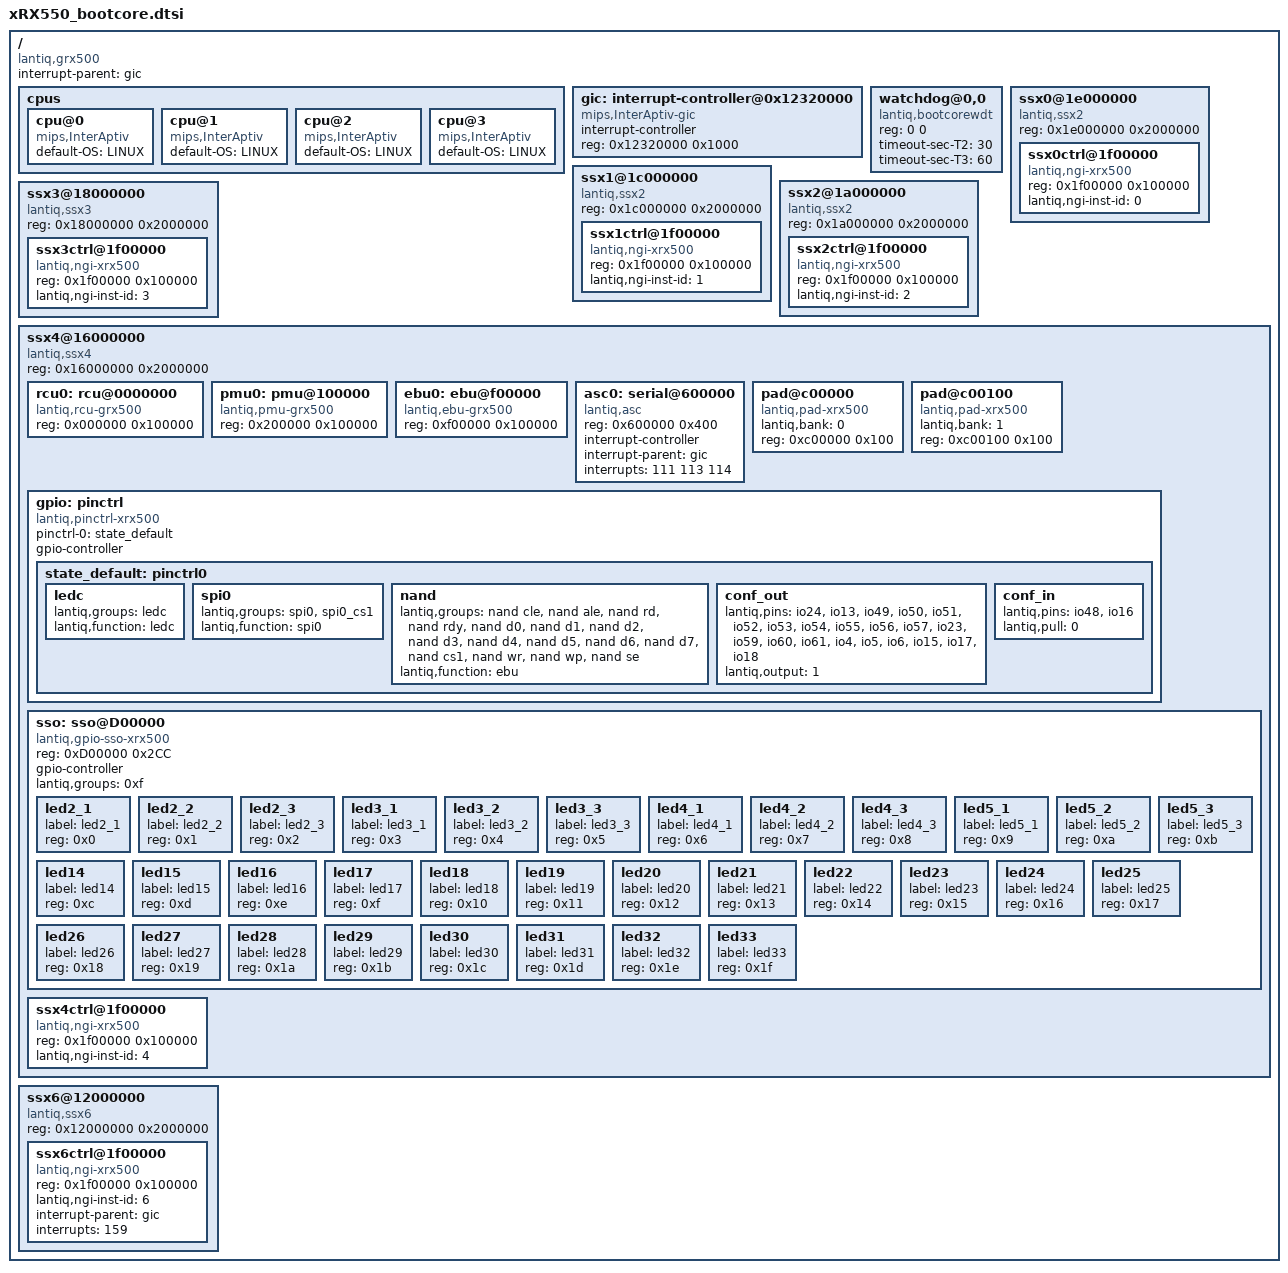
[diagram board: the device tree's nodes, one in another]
/ {
	#address-cells = <1>;
	#size-cells = <1>;
	compatible = "lantiq,grx500","lantiq,xway";
        interrupt-parent = <&gic>;

	cpus {
		cpu@0 {
			compatible = "mips,InterAptiv";
			default-OS = "LINUX";
		};
		cpu@1 {
			compatible = "mips,InterAptiv";
			default-OS = "LINUX";
		};
		cpu@2 {
			compatible = "mips,InterAptiv";
			default-OS = "LINUX";
		};
		cpu@3 {
			compatible = "mips,InterAptiv";
			default-OS = "LINUX";
		};
	};

        gic: interrupt-controller@0x12320000 {
                compatible = "mips,InterAptiv-gic";
                #interrupt-cells = <1>;
                #address-cells = <0>;
                interrupt-controller;
                reg = <0x12320000 0x1000>;
        };

	watchdog@0,0 {
		compatible = "lantiq,bootcorewdt";
		reg = <0 0>;
		timeout-sec-T2 = <30>;
		timeout-sec-T3 = <60>;
	};

	ssx0@1e000000 {
		#address-cells = <1>;
		#size-cells = <1>;
		compatible = "lantiq,ssx2", "simple-bus";
		reg = <0x1e000000 0x2000000>;
		ranges = <0x0 0x1e000000 0x02000000>;

		ssx0ctrl@1f00000 {
			#address-cells = <1>;
			#size-cells = <1>;
			compatible = "lantiq,ngi-xrx500";
			reg = <0x1f00000 0x100000>;
			/*ranges = <0x0 0x1f00000 0x0100000>;*/
			lantiq,ngi-inst-id = <0>;
		};
	};

	ssx1@1c000000 {
		#address-cells = <1>;
		#size-cells = <1>;
		compatible = "lantiq,ssx2", "simple-bus";
		reg = <0x1c000000 0x2000000>;
		ranges = <0x0 0x1c000000 0x02000000>;

		ssx1ctrl@1f00000 {
			#address-cells = <1>;
			#size-cells = <1>;
			compatible = "lantiq,ngi-xrx500";
			reg = <0x1f00000 0x100000>;
			/*ranges = <0x0 0x1f00000 0x0100000>;*/
			lantiq,ngi-inst-id = <1>;
		};
	};

	ssx2@1a000000 {
		#address-cells = <1>;
		#size-cells = <1>;
		compatible = "lantiq,ssx2", "simple-bus";
		reg = <0x1a000000 0x2000000>;
		ranges = <0x0 0x1a000000 0x02000000>;

		ssx2ctrl@1f00000 {
			#address-cells = <1>;
			#size-cells = <1>;
			compatible = "lantiq,ngi-xrx500";
			reg = <0x1f00000 0x100000>;
			/*ranges = <0x0 0x1f00000 0x0100000>;*/
			lantiq,ngi-inst-id = <2>;
		};
	};

	ssx3@18000000 {
		#address-cells = <1>;
		#size-cells = <1>;
		compatible = "lantiq,ssx3", "simple-bus";
		reg = <0x18000000 0x2000000>;
		ranges = <0x0 0x18000000 0x02000000>;

		ssx3ctrl@1f00000 {
			#address-cells = <1>;
			#size-cells = <1>;
			compatible = "lantiq,ngi-xrx500";
			reg = <0x1f00000 0x100000>;
			ranges = <0x0 0x1f00000 0x0100000>;
			lantiq,ngi-inst-id = <3>;
		};
	};

	ssx4@16000000 {
		#address-cells = <1>;
		#size-cells = <1>;
		compatible = "lantiq,ssx4", "simple-bus";
		reg = <0x16000000 0x2000000>;
		ranges = <0x0 0x16000000 0x02000000>;

		rcu0: rcu@0000000 {
			compatible = "lantiq,rcu-grx500";
			reg = <0x000000 0x100000>;
		};

		pmu0: pmu@100000 {
			compatible = "lantiq,pmu-grx500";
			reg = <0x200000 0x100000>;
		};

		ebu0: ebu@f00000 {
			compatible = "lantiq,ebu-grx500";
			reg = <0xf00000 0x100000>;
			reg-names = "ebunand_reg", "hsnand_reg";
		};

                asc0: serial@600000 {
                        compatible = "lantiq,asc";
                        reg = <0x600000 0x400>;
                        interrupt-controller;
                        interrupt-parent = <&gic>;
                        interrupts = <111 113 114>;
                };

		pad@c00000{
			compatible = "lantiq,pad-xrx500";
			lantiq,bank = <0>;
			reg = <0xc00000 0x100>;
		};

		pad@c00100{
			compatible = "lantiq,pad-xrx500";
			lantiq,bank = <1>;
			reg = <0xc00100 0x100>;
		};

		gpio: pinctrl {
			compatible = "lantiq,pinctrl-xrx500";
			pinctrl-names = "default";
			pinctrl-0 = <&state_default>;

			#gpio-cells = <2>;
			gpio-controller;

			state_default: pinctrl0 {
				ledc {
						lantiq,groups = "ledc";
						lantiq,function = "ledc";
					};
				spi0 {
					lantiq,groups = "spi0", "spi0_cs1";
					lantiq,function = "spi0";
				};
				nand {
					lantiq,groups = "nand cle", "nand ale",
							"nand rd", "nand rdy",
                            				"nand d0", "nand d1", 
							"nand d2", "nand d3",
                            				"nand d4", "nand d5",
                            				"nand d6", "nand d7", 
							"nand cs1", "nand wr", 
							"nand wp", "nand se";
					lantiq,function = "ebu";
				};

				conf_out {
					lantiq,pins = "io24", "io13", "io49", /* nand cle, ale and rd */
							"io50", "io51", "io52",
							"io53", "io54", "io55",
							"io56", "io57", "io23",
							"io59", "io60", "io61",
							"io4", "io5", "io6", /* LEDC */
							"io15", "io17", "io18"; /* spi */
					lantiq,output = <1>;
				};
				conf_in {
					lantiq,pins = "io48", /* nand rdy */
						      "io16"; /* spi in */
					lantiq,pull = <0>;
				};
			};
		};
		sso: sso@D00000 {
			compatible = "lantiq,gpio-sso-xrx500";
			reg = <0xD00000 0x2CC>;
			#gpio-cells = <2>;
			gpio-controller;

			lantiq,groups = <0xf>;
			/* lantiq,phy1 = <0x7>; */
			/* lantiq,phy2 = <0x7>; */
			/* lantiq,rising; */
			#address-cells = <1>;
                        #size-cells = <0>;
                        led2_1 {
                                label = "led2_1";
                                reg = <0x0>;
                        };
                        led2_2 {
                                label = "led2_2";
                                reg = <0x1>;
                        };
                        led2_3 {
                                label = "led2_3";
                                reg = <0x2>;
                        };
                        led3_1 {
                                label = "led3_1";
                                reg = <0x3>;
                        };
                        led3_2 {
                                label = "led3_2";
                                reg = <0x4>;
                        };
                        led3_3 {
                                label = "led3_3";
                                reg = <0x5>;
                        };
                        led4_1 {
                                label = "led4_1";
                                reg = <0x6>;
                        };
                        led4_2 {
                                label = "led4_2";
                                reg = <0x7>;
                        };
                        led4_3 {
                                label = "led4_3";
                                reg = <0x8>;
                        };
                        led5_1 {
                                label = "led5_1";
                                reg = <0x9>;
                        };
                        led5_2 {
                                label = "led5_2";
                                reg = <0xa>;
                        };
                        led5_3 {
                                label = "led5_3";
                                reg = <0xb>;
                        };
                        led14 {
                                label = "led14";
                                reg = <0xc>;
                        };
                        led15 {
                                label = "led15";
                                reg = <0xd>;
                        };
                        led16 {
                                label = "led16";
                                reg = <0xe>;
                        };
                        led17 {
                                label = "led17";
                                reg = <0xf>;
                        };
                        led18 {
                                label = "led18";
                                reg = <0x10>;
                        };
                        led19 {
                                label = "led19";
                                reg = <0x11>;
                        };
                        led20 {
                                label = "led20";
                                reg = <0x12>;
                        };
                        led21 {
                                label = "led21";
                                reg = <0x13>;
                        };
                        led22 {
                                label = "led22";
                                reg = <0x14>;
                        };
                        led23 {
                                label = "led23";
                                reg = <0x15>;
                        };
                        led24 {
                                label = "led24";
                                reg = <0x16>;
                        };
                        led25 {
                                label = "led25";
                                reg = <0x17>;
                        };
                        led26 {
                                label = "led26";
                                reg = <0x18>;
                        };
                        led27 {
                                label = "led27";
                                reg = <0x19>;
                        };
                        led28 {
                                label = "led28";
                                reg = <0x1a>;
                        };
                        led29 {
                                label = "led29";
                                reg = <0x1b>;
                        };
                        led30 {
                                label = "led30";
                                reg = <0x1c>;
                        };
                        led31 {
                                label = "led31";
                                reg = <0x1d>;
                        };
                        led32 {
                                label = "led32";
                                reg = <0x1e>;
                        };
                        led33 {
                                label = "led33";
                                reg = <0x1f>;
                        };
		};

		ssx4ctrl@1f00000 {
			#address-cells = <1>;
			#size-cells = <1>;
			compatible = "lantiq,ngi-xrx500";
			reg = <0x1f00000 0x100000>;
			/*ranges = <0x0 0x1f00000 0x0100000>;*/
			lantiq,ngi-inst-id = <4>;
		};
	};

	ssx6@12000000 {
		#address-cells = <1>;
		#size-cells = <1>;
		compatible = "lantiq,ssx6", "simple-bus";
		reg = <0x12000000 0x2000000>;
		ranges = <0x0 0x12000000 0x02000000>;

		ssx6ctrl@1f00000 {
			#address-cells = <1>;
			#size-cells = <1>;
			compatible = "lantiq,ngi-xrx500";
			reg = <0x1f00000 0x100000>;
			/*ranges = <0x0 0x13f00000 0x0100000>;*/
			lantiq,ngi-inst-id = <6>;
			interrupt-parent = <&gic>;
			interrupts = <159>;
		};
	};

};
